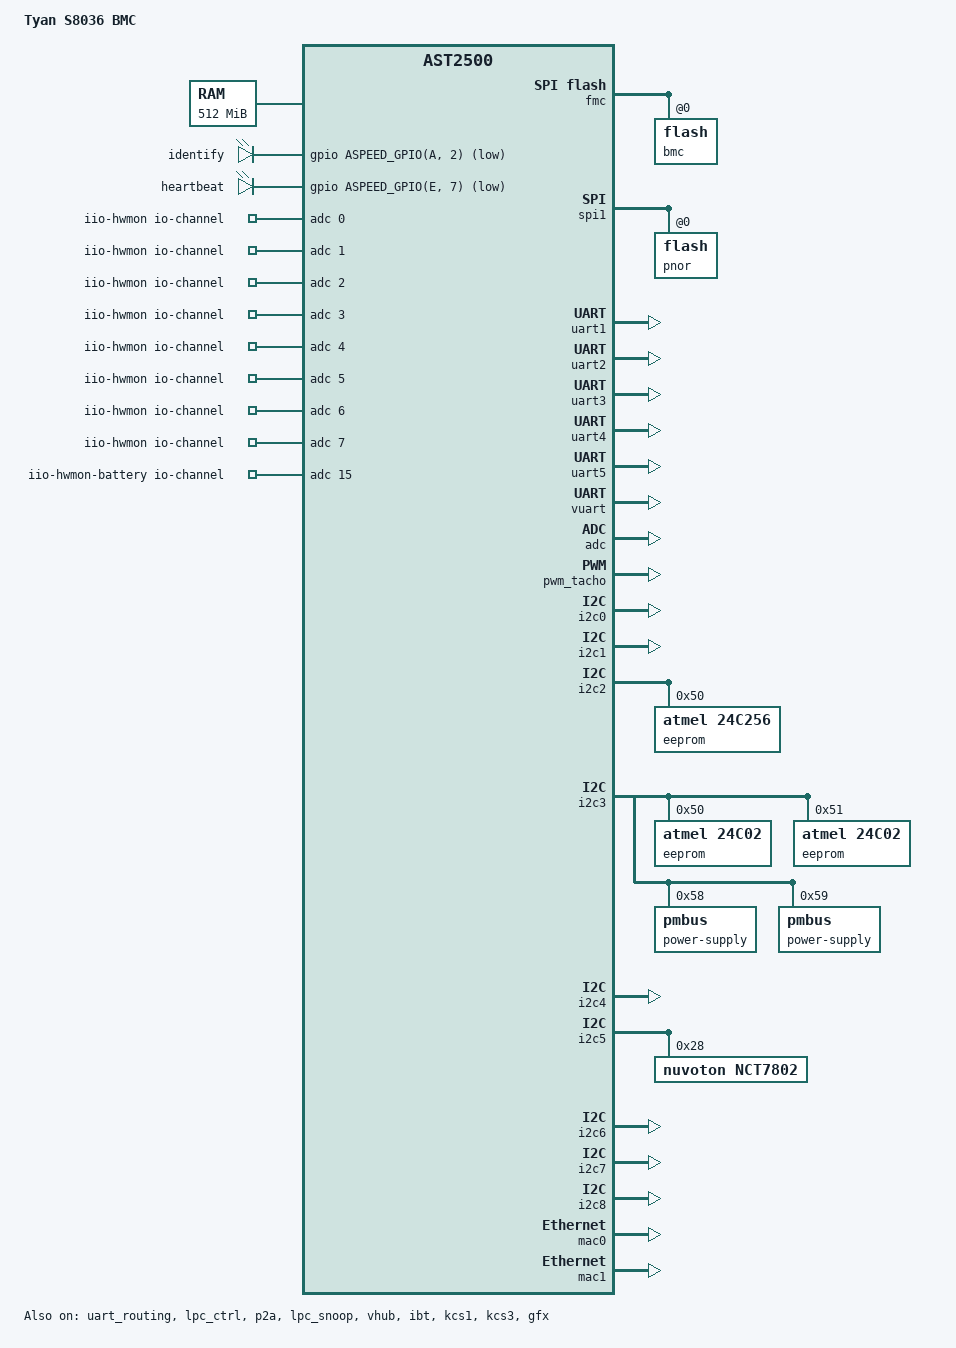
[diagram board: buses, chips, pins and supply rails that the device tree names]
/dts-v1/;
#include "aspeed-g5.dtsi"
#include <dt-bindings/gpio/aspeed-gpio.h>
#include <dt-bindings/interrupt-controller/irq.h>
/ {
	model = "Tyan S8036 BMC";
	compatible = "tyan,s8036-bmc", "aspeed,ast2500";
	chosen {
		stdout-path = &uart5;
		bootargs = "console=ttyS4,115200 earlycon";
	};
	memory@80000000 {
		device_type = "memory";
		reg = <0x80000000 0x20000000>;
	};
	reserved-memory {
		#address-cells = <1>;
		#size-cells = <1>;
		ranges;
		p2a_memory: region@987f0000 {
			no-map;
			reg = <0x987f0000 0x00010000>;  
		};
		vga_memory: framebuffer@9f000000 {
			no-map;
			reg = <0x9f000000 0x01000000>;  
		};
		gfx_memory: framebuffer {
			size = <0x01000000>;  
			alignment = <0x01000000>;
			compatible = "shared-dma-pool";
			reusable;
		};
	};
	leds {
		compatible = "gpio-leds";
		identify {
			gpios = <&gpio ASPEED_GPIO(A, 2) GPIO_ACTIVE_LOW>;
		};
		heartbeat {
			gpios = <&gpio ASPEED_GPIO(E, 7) GPIO_ACTIVE_LOW>;
		};
	};
	iio-hwmon {
		compatible = "iio-hwmon";
		io-channels = <&adc 0>, <&adc 1>, <&adc 2>, <&adc 3>,
			<&adc 4>, <&adc 5>, <&adc 6>, <&adc 7>,
			<&adc 8>, <&adc 9>, <&adc 10>, <&adc 11>,
			<&adc 12>, <&adc 13>, <&adc 14>;
	};
	iio-hwmon-battery {
		compatible = "iio-hwmon";
		io-channels = <&adc 15>;
	};
};
&fmc {
	status = "okay";
	flash@0 {
		label = "bmc";
		status = "okay";
		m25p,fast-read;
#include "openbmc-flash-layout.dtsi"
	};
};
&spi1 {
	status = "okay";
	pinctrl-names = "default";
	pinctrl-0 = <&pinctrl_spi1_default>;
	flash@0 {
		status = "okay";
		label = "pnor";
		m25p,fast-read;
	};
};
&uart1 {
	status = "okay";
	pinctrl-names = "default";
	pinctrl-0 = <&pinctrl_txd1_default
			&pinctrl_rxd1_default>;
};
&uart2 {
	status = "okay";
	pinctrl-names = "default";
	pinctrl-0 = <&pinctrl_txd2_default
			&pinctrl_rxd2_default>;
};
&uart3 {
	status = "okay";
};
&uart4 {
	status = "okay";
};
&uart5 {
	status = "okay";
};
&uart_routing {
	status = "okay";
};
&vuart {
	status = "okay";
	aspeed,lpc-io-reg = <0xffff>;
	aspeed,lpc-interrupts = <15 IRQ_TYPE_LEVEL_HIGH>;
};
&lpc_ctrl {
	status = "okay";
};
&p2a {
	status = "okay";
	memory-region = <&p2a_memory>;
};
&lpc_snoop {
	status = "okay";
	snoop-ports = <0x80>;
};
&adc {
	status = "okay";
};
&vhub {
	status = "okay";
};
&pwm_tacho {
	status = "okay";
	pinctrl-names = "default";
	pinctrl-0 = <&pinctrl_pwm0_default
			&pinctrl_pwm1_default
			&pinctrl_pwm3_default
			&pinctrl_pwm4_default>;
	fan@0 {
		reg = <0x00>;
		aspeed,fan-tach-ch = /bits/ 8 <0x00>;
	};
	fan@2 {
		reg = <0x03>;
		aspeed,fan-tach-ch = /bits/ 8 <0x02>;
	};
	fan@3 {
		reg = <0x03>;
		aspeed,fan-tach-ch = /bits/ 8 <0x03>;
	};
	fan@4 {
		reg = <0x03>;
		aspeed,fan-tach-ch = /bits/ 8 <0x04>;
	};
	fan@5 {
		reg = <0x03>;
		aspeed,fan-tach-ch = /bits/ 8 <0x05>;
	};
	fan@6 {
		reg = <0x04>;
		aspeed,fan-tach-ch = /bits/ 8 <0x06>;
	};
	fan@7 {
		reg = <0x04>;
		aspeed,fan-tach-ch = /bits/ 8 <0x07>;
	};
};
&i2c0 {
	status = "okay";
};
&i2c1 {
	status = "okay";
};
&i2c2 {
	status = "okay";
	eeprom@50 {
		compatible = "atmel,24c256";
		reg = <0x50>;
	};
};
&i2c3 {
	status = "okay";
	eeprom@50 {
		compatible = "atmel,24c02";
		reg = <0x50>;
	};
	eeprom@51 {
		compatible = "atmel,24c02";
		reg = <0x51>;
	};
	power-supply@58 {
		compatible = "pmbus";
		reg = <0x58>;
	};
	power-supply@59 {
		compatible = "pmbus";
		reg = <0x59>;
	};
};
&i2c4 {
	status = "okay";
};
&i2c5 {
	status = "okay";
	nct7802@28 {
		compatible = "nuvoton,nct7802";
		reg = <0x28>;
		#address-cells = <1>;
		#size-cells = <0>;
		channel@0 {  
			reg = <0>;
			status = "okay";
		};
		channel@1 {  
			reg = <1>;
			status = "okay";
			sensor-type = "temperature";
			temperature-mode = "thermistor";
		};
		channel@2 {  
			reg = <2>;
			status = "okay";
			sensor-type = "temperature";
			temperature-mode = "thermistor";
		};
		channel@3 {  
			reg = <3>;
			status = "okay";
			sensor-type = "temperature";
		};
	};
};
&i2c6 {
	status = "okay";
};
&i2c7 {
	status = "okay";
};
&i2c8 {
	status = "okay";
};
&mac0 {
	status = "okay";
	use-ncsi;
	pinctrl-names = "default";
	pinctrl-0 = <&pinctrl_rmii1_default>;
};
&mac1 {
	status = "okay";
	pinctrl-names = "default";
	pinctrl-0 = <&pinctrl_rgmii2_default &pinctrl_mdio2_default>;
};
&ibt {
	status = "okay";
};
&kcs1 {
	status = "okay";
	aspeed,lpc-io-reg = <0xca8>;
};
&kcs3 {
	status = "okay";
	aspeed,lpc-io-reg = <0xca2>;
	aspeed,lpc-interrupts = <1 IRQ_TYPE_LEVEL_HIGH>;
};
&gfx {
	status = "okay";
	memory-region = <&gfx_memory>;
};
&gpio {
	status = "okay";
	gpio-line-names =
	 		"",
	 		"",
	 		"led-identify",  
	 		"",
	 		"",
	 		"",
	 		"",
	 		"",
	 	"","","","","","","","",
	 	"","","","","","","","",
	 		"",
	 		"",
	 		"power-chassis-good",  
	 		"platform-reset",  
	 		"",
	 		"",
	 		"",
	 		"",
	 		"power-button",  
	 		"power-chassis-control",  
	 		"reset-button",  
	 		"reset-control",  
	 		"nmi-button",  
	 		"nmi-control",  
	 		"TSI_RESERT",
	 		"led-heartbeat",  
	 		"",
	 		"clear-cmos-control",  
	 		"",
	 		"",
	 		"led-fault",  
	 		"BMC_SYS_FAULT_LED_L",
	 		"BMC_ASSERT_BIOS_WP_L",
	 		"",
	 	"","","","","","","","",
	 	"","","","","","","","",
	 	"","","","","","","","",
	 	"","","","","","","","",
	 	"","","","","","","","",
	 	"","","","","","","","",
	 	"","","","","","","","",
	 	"","","","","","","","",
	 	"","","","","","","","",
	 	"","","","","","","","",
	 		"",
	 		"",
	 		"",
	 		"",
	 		"",
	 		"",
	 		"id-button",  
	 		"",
	 	"","","","","","","","",
	 	"","","","","","","","",
	 	"","","","","","","","",
	 	"","","","","","","","",
	 	"","","","","","","","",
	 	"","","","","","","","",
	 	"","","","","","","","",
	 	"","","","","","","","",
	 	"","","",
	 		"post-complete",  
	 	"","","","",
	 		"",
	 		"",
	 		"",
	 		"",
	 		"",
	 		"",
	 		"",
	 		"BMC_ASSERT_BMC_READY",
	 		"BMC_SPD_SEL",
	 	"","","","","","","";
};
